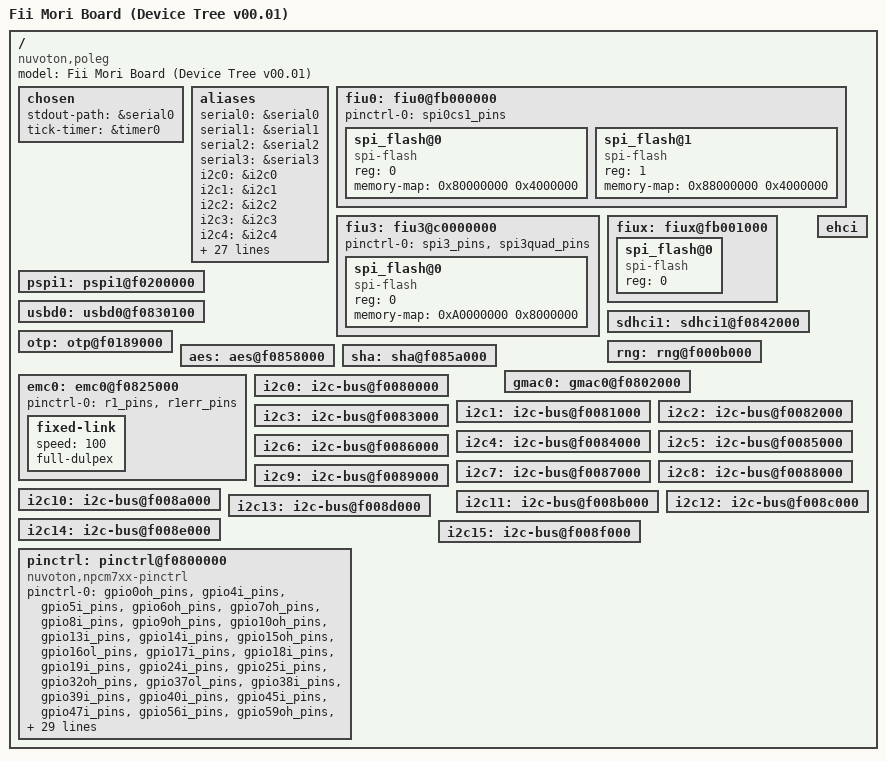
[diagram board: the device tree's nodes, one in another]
// SPDX-License-Identifier: GPL-2.0
// Copyright (c) 2022 Fii USA Inc. 
// Maintainer: Charles Boyer <Charles.Boyer@fii-na.com>

/dts-v1/;
#include "nuvoton-common-npcm7xx.dtsi"
#include "nuvoton-npcm730-mori-pincfg.dtsi"

/ {
	model = "Fii Mori Board (Device Tree v00.01)";
	compatible = "nuvoton,poleg", "mori";

	chosen {
		stdout-path = &serial0;
		tick-timer = &timer0;
	};

	aliases {
		serial0 = &serial0;
		serial1 = &serial1;
		serial2 = &serial2;
		serial3 = &serial3;
		i2c0 = &i2c0;
		i2c1 = &i2c1;
		i2c2 = &i2c2;
		i2c3 = &i2c3;
		i2c4 = &i2c4;
		i2c5 = &i2c5;
		i2c6 = &i2c6;
		i2c7 = &i2c7;
		i2c8 = &i2c8;
		i2c9 = &i2c9;
		i2c10 = &i2c10;
		i2c11 = &i2c11;
		i2c12 = &i2c12;
		i2c13 = &i2c13;
		i2c14 = &i2c14;
		i2c15 = &i2c15;
		spi0 = &fiu0;
		spi3 = &fiu3;
		spi4 = &fiux;
		spi5 = &pspi1;
		mmc1 = &sdhci1;
		gpio0 = &gpio0;
		gpio1 = &gpio1;
		gpio2 = &gpio2;
		gpio3 = &gpio3;
		gpio4 = &gpio4;
		gpio5 = &gpio5;
		gpio6 = &gpio6;
		gpio7 = &gpio7;
		usb0 = &usbd0;
		eth0 = &emc0;
		eth1 = &gmac0;
	};

	fiu0: fiu0@fb000000 {
		pinctrl-names = "default";
		pinctrl-0 = <&spi0cs1_pins>;
		status = "okay";
		spi_flash@0 {
			compatible = "spi-flash";
			reg = <0>; /* Chip select 0 */
			memory-map = <0x80000000 0x4000000>;
		};
		spi_flash@1 {
			compatible = "spi-flash";
			reg = <1>;
			memory-map = <0x88000000 0x4000000>;
		};
	};

	fiu3: fiu3@c0000000 {
		status = "okay";
		pinctrl-names = "default";
		pinctrl-0 = <&spi3_pins
			&spi3quad_pins>;
		spi_flash@0 {
			compatible = "spi-flash";
			reg = <0>; /* Chip select 0 */
			memory-map = <0xA0000000 0x8000000>;
		};
	};

	fiux: fiux@fb001000 {
		status = "okay";
		spi_flash@0 {
			compatible = "spi-flash";
			reg = <0>; /* Chip select 0 */
		 };
	};

	pspi1: pspi1@f0200000 {
		status = "okay";
	};

	usbd0: usbd0@f0830100 {
		status = "okay";
	};


	sdhci1: sdhci1@f0842000 {
		status = "okay";
	};

	otp: otp@f0189000 {
		status = "okay";
	};

	rng: rng@f000b000 {
		status = "okay";
	};

	aes: aes@f0858000 {
		status = "okay";
	};

	sha: sha@f085a000 {
		status = "okay";
	};

	gmac0: gmac0@f0802000 {
		status = "okay";
	};

	emc0: emc0@f0825000 {
		status = "okay";
		pinctrl-names = "default";
		pinctrl-0 = <&r1_pins
			&r1err_pins>;
		fixed-link {
			speed = <100>;
			full-dulpex;
		};
	};

	ehci: ehci {
		status = "okay";
	};

	i2c0: i2c-bus@f0080000 {
		status = "okay";
	};

	i2c1: i2c-bus@f0081000 {
		status = "okay";
	};

	i2c2: i2c-bus@f0082000 {
		status = "okay";
	};

	i2c3: i2c-bus@f0083000 {
		status = "okay";
	};

	i2c4: i2c-bus@f0084000 {
		status = "okay";
	};

	i2c5: i2c-bus@f0085000 {
		status = "okay";
	};

	i2c6: i2c-bus@f0086000 {
		status = "okay";
	};

	i2c7: i2c-bus@f0087000 {
		status = "okay";
	};

	i2c8: i2c-bus@f0088000 {
		status = "okay";
	};

	i2c9: i2c-bus@f0089000 {
		status = "okay";
	};

	i2c10: i2c-bus@f008a000 {
		status = "okay";
	};

	i2c11: i2c-bus@f008b000 {
		status = "okay";
	};

	i2c12: i2c-bus@f008c000 {
		status = "okay";
	};

	i2c13: i2c-bus@f008d000 {
		status = "okay";
	};

	i2c14: i2c-bus@f008e000 {
		status = "okay";
	};

	i2c15: i2c-bus@f008f000 {
		status = "okay";
	};

	pinctrl: pinctrl@f0800000 {
		compatible = "nuvoton,npcm7xx-pinctrl";
		pinctrl-names = "default";
		pinctrl-0 = <
			&gpio0oh_pins
			&gpio4i_pins
			&gpio5i_pins
			&gpio6oh_pins
			&gpio7oh_pins
			&gpio8i_pins
			&gpio9oh_pins
			&gpio10oh_pins
			&gpio13i_pins
			&gpio14i_pins
			&gpio15oh_pins
			&gpio16ol_pins
			&gpio17i_pins
			&gpio18i_pins
			&gpio19i_pins
			&gpio24i_pins
			&gpio25i_pins
			&gpio32oh_pins
			&gpio37ol_pins
			&gpio38i_pins
			&gpio39i_pins
			&gpio40i_pins
			&gpio45i_pins
			&gpio47i_pins
			&gpio56i_pins
			&gpio59oh_pins
			&gpio64i_pins
			&gpio65i_pins
			&gpio66ol_pins
			&gpio67ol_pins
			&gpio68oh_pins
			&gpio69oh_pins
			&gpio70ol_pins
			&gpio71i_pins
			&gpio72oh_pins
			&gpio73i_pins
			&gpio74ol_pins
			&gpio75ol_pins
			&gpio76oh_pins
			&gpio77oh_pins
			&gpio78i_pins
			&gpio79i_pins
			&gpio80ol_pins
			&gpio81oh_pins
			&gpio84oh_pins
			&gpio85oh_pins
			&gpio86oh_pins
			&gpio87oh_pins
			&gpio88oh_pins
			&gpio89oh_pins
			&gpio90oh_pins
			&gpio91oh_pins
			&gpio92oh_pins
			&gpio93i_pins
			&gpio94i_pins
			&gpio95i_pins
			&gpio120oh_pins
			&gpio121i_pins
			&gpio122i_pins
			&gpio123i_pins
			&gpio124i_pins
			&gpio126oh_pins
			&gpio136i_pins
			&gpio137oh_pins
			&gpio138i_pins
			&gpio139i_pins
			&gpio140i_pins
			&gpio141i_pins
			&gpio142ol_pins
			&gpio145oh_pins
			&gpio146i_pins
			&gpio160ol_pins
			&gpio162i_pins
			&gpio169i_pins
			&gpio190i_pins
			&gpio195i_pins
			&gpio196ol_pins
			&gpio197i_pins
			&gpio198oh_pins
			&gpio199i_pins
			&gpio200oh_pins
			&gpio202i_pins
			&gpio204i_pins
			&gpio205oh_pins
			&gpio206oh_pins
			&gpio207oh_pins
			&gpio212oh_pins
			&gpio214i_pins
			&gpio215oh_pins
			&gpio216oh_pins
			&gpio217ol_pins
			&gpio218ol_pins
			&gpio224i_pins
			&gpio228i_pins
			&gpio230i_pins
			&gpio231i_pins

			// BSP RX/TX
			&bmcuart0a_pins /* BSP RX/TX */
		>;
	};
};
